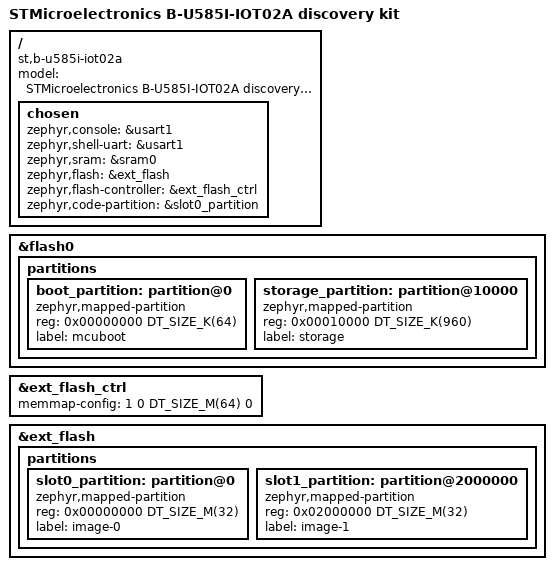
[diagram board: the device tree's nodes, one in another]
/*
 * Copyright (c) 2026 STMicroelectronics
 *
 * SPDX-License-Identifier: Apache-2.0
 */

/dts-v1/;
#include "b_u585i_iot02a-common.dtsi"

/ {
	compatible = "st,b-u585i-iot02a";
	model = "STMicroelectronics B-U585I-IOT02A discovery kit";

	chosen {
		zephyr,console = &usart1;
		zephyr,shell-uart = &usart1;
		zephyr,sram = &sram0;
		zephyr,flash = &ext_flash;
		zephyr,flash-controller = &ext_flash_ctrl;
		zephyr,code-partition = &slot0_partition;
	};
};

&flash0 {
	partitions {
		#address-cells = <1>;
		#size-cells = <1>;

		/* Set the partitions with first MB to make use of the whole Bank1 */
		boot_partition: partition@0 {
			compatible = "zephyr,mapped-partition";
			reg = <0x00000000 DT_SIZE_K(64)>;
			label = "mcuboot";
		};

		storage_partition: partition@10000 {
			compatible = "zephyr,mapped-partition";
			reg = <0x00010000 DT_SIZE_K(960)>;
			label = "storage";
		};
	};
};

&ext_flash_ctrl {
	/* Allow Rd in MemoryMapped mode (permission = 0) */
	memmap-config = <1 0 DT_SIZE_M(64) 0>;
};

&ext_flash {
	partitions {
		ranges;
		#address-cells = <1>;
		#size-cells = <1>;

		slot0_partition: partition@0 {
			compatible = "zephyr,mapped-partition";
			reg = <0x00000000 DT_SIZE_M(32)>;
			label = "image-0";
		};

		slot1_partition: partition@2000000 {
			compatible = "zephyr,mapped-partition";
			reg = <0x02000000 DT_SIZE_M(32)>;
			label = "image-1";
		};
	};
};
